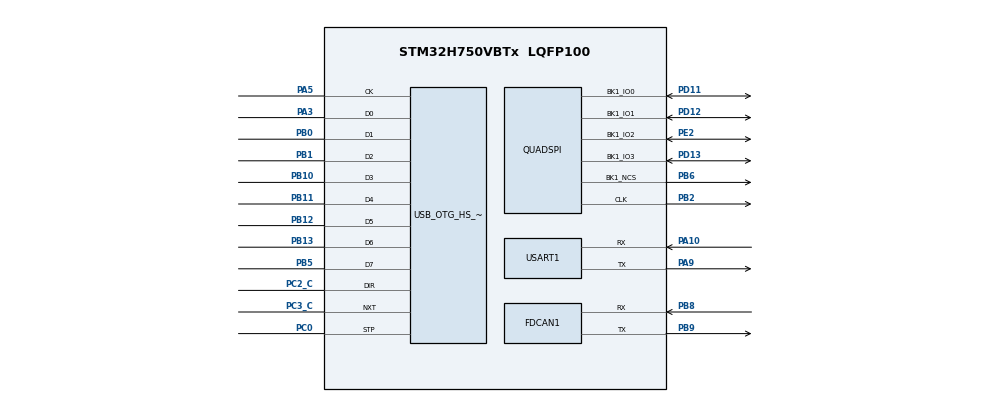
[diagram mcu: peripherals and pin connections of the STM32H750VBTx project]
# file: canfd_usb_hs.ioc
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CORTEX_M7.AccessPermission-Cortex_Memory_Protection_Unit_Region0_Settings=MPU_REGION_FULL_ACCESS
CORTEX_M7.AccessPermission-Cortex_Memory_Protection_Unit_Region1_Settings=MPU_REGION_PRIV_RO_URO
CORTEX_M7.AccessPermission_Spec=MPU_REGION_FULL_ACCESS
CORTEX_M7.BaseAddress-Cortex_Memory_Protection_Unit_Region1_Settings=0x8000000
CORTEX_M7.BaseAddress_Spec=0x24000000
CORTEX_M7.CPU_DCache=Enabled
CORTEX_M7.CPU_ICache=Enabled
CORTEX_M7.DisableExec_Spec=MPU_INSTRUCTION_ACCESS_ENABLE
CORTEX_M7.Enable-Cortex_Memory_Protection_Unit_Region0_Settings=MPU_REGION_ENABLE
CORTEX_M7.Enable-Cortex_Memory_Protection_Unit_Region1_Settings=MPU_REGION_ENABLE
CORTEX_M7.IsBufferable-Cortex_Memory_Protection_Unit_Region1_Settings=MPU_ACCESS_BUFFERABLE
CORTEX_M7.IsBufferable_Spec=MPU_ACCESS_BUFFERABLE
CORTEX_M7.IsCacheable-Cortex_Memory_Protection_Unit_Region1_Settings=MPU_ACCESS_CACHEABLE
CORTEX_M7.IsCacheable_Spec=MPU_ACCESS_CACHEABLE
CORTEX_M7.IsShareable_Spec=MPU_ACCESS_NOT_SHAREABLE
CORTEX_M7.MPU_Control=MPU_PRIVILEGED_DEFAULT
CORTEX_M7.Size-Cortex_Memory_Protection_Unit_Region0_Settings=MPU_REGION_SIZE_64KB
CORTEX_M7.Size-Cortex_Memory_Protection_Unit_Region1_Settings=MPU_REGION_SIZE_128KB
CORTEX_M7.Size_Spec=MPU_REGION_SIZE_512KB
CORTEX_M7.SubRegionDisable_Spec=0x0
CORTEX_M7.TypeExtField-Cortex_Memory_Protection_Unit_Region0_Settings=MPU_TEX_LEVEL1
CORTEX_M7.TypeExtField_Spec=MPU_TEX_LEVEL1
CORTEX_M7.default_mode_Activation=1
Dma.Request0=USART1_RX
Dma.Request1=USART1_TX
Dma.USART1_RX.0.Direction=DMA_PERIPH_TO_MEMORY
Dma.USART1_RX.0.EventEnable=DISABLE
Dma.USART1_RX.0.FIFOMode=DMA_FIFOMODE_DISABLE
Dma.USART1_RX.0.Instance=DMA1_Stream0
Dma.USART1_RX.0.MemDataAlignment=DMA_MDATAALIGN_BYTE
Dma.USART1_RX.0.MemInc=DMA_MINC_ENABLE
Dma.USART1_RX.0.Mode=DMA_CIRCULAR
Dma.USART1_RX.0.PeriphDataAlignment=DMA_PDATAALIGN_BYTE
Dma.USART1_RX.0.PeriphInc=DMA_PINC_DISABLE
Dma.USART1_RX.0.Polarity=HAL_DMAMUX_REQ_GEN_RISING
Dma.USART1_RX.0.Priority=DMA_PRIORITY_LOW
Dma.USART1_RX.0.RequestNumber=1
Dma.USART1_RX.0.SignalID=NONE
Dma.USART1_RX.0.SyncEnable=DISABLE
Dma.USART1_RX.0.SyncPolarity=HAL_DMAMUX_SYNC_NO_EVENT
Dma.USART1_RX.0.SyncRequestNumber=1
Dma.USART1_RX.0.SyncSignalID=NONE
Dma.USART1_TX.1.Direction=DMA_MEMORY_TO_PERIPH
Dma.USART1_TX.1.EventEnable=DISABLE
Dma.USART1_TX.1.FIFOMode=DMA_FIFOMODE_DISABLE
Dma.USART1_TX.1.Instance=DMA1_Stream1
Dma.USART1_TX.1.MemDataAlignment=DMA_MDATAALIGN_BYTE
Dma.USART1_TX.1.MemInc=DMA_MINC_ENABLE
Dma.USART1_TX.1.Mode=DMA_NORMAL
Dma.USART1_TX.1.PeriphDataAlignment=DMA_PDATAALIGN_BYTE
Dma.USART1_TX.1.PeriphInc=DMA_PINC_DISABLE
Dma.USART1_TX.1.Polarity=HAL_DMAMUX_REQ_GEN_RISING
Dma.USART1_TX.1.Priority=DMA_PRIORITY_LOW
Dma.USART1_TX.1.RequestNumber=1
Dma.USART1_TX.1.SignalID=NONE
Dma.USART1_TX.1.SyncEnable=DISABLE
Dma.USART1_TX.1.SyncPolarity=HAL_DMAMUX_SYNC_NO_EVENT
Dma.USART1_TX.1.SyncRequestNumber=1
Dma.USART1_TX.1.SyncSignalID=NONE
FDCAN1.AutoRetransmission=ENABLE
FDCAN1.CalculateBaudRateNominal=500000
FDCAN1.CalculateTimeBitNominal=2000
FDCAN1.CalculateTimeQuantumNominal=25.0
FDCAN1.DataPrescaler=2
FDCAN1.DataSyncJumpWidth=5
FDCAN1.DataTimeSeg1=14
FDCAN1.DataTimeSeg2=5
FDCAN1.ExtFiltersNbr=32
FDCAN1.FrameFormat=FDCAN_FRAME_FD_BRS
FDCAN1.NominalPrescaler=2
FDCAN1.NominalSyncJumpWidth=16
FDCAN1.NominalTimeSeg1=63
FDCAN1.NominalTimeSeg2=16
FDCAN1.RxBufferSize=FDCAN_DATA_BYTES_64
FDCAN1.RxFifo0ElmtSize=FDCAN_DATA_BYTES_64
FDCAN1.RxFifo0ElmtsNbr=32
FDCAN1.RxFifo1ElmtSize=FDCAN_DATA_BYTES_64
FDCAN1.StdFiltersNbr=64
FDCAN1.TransmitPause=ENABLE
FDCAN1.TxElmtSize=FDCAN_DATA_BYTES_64
FDCAN1.TxFifoQueueElmtsNbr=16
FREERTOS.Tasks01=defaultTask,0,128,StartDefaultTask,Default,NULL,Dynamic,NULL,NULL
FREERTOS.configCHECK_FOR_STACK_OVERFLOW=2
FREERTOS.configRECORD_STACK_HIGH_ADDRESS=1
FREERTOS.configUSE_COUNTING_SEMAPHORES=1
FREERTOS.configUSE_IDLE_HOOK=1
FREERTOS.configUSE_MALLOC_FAILED_HOOK=1
FREERTOS.configUSE_RECURSIVE_MUTEXES=1
HASH.SecureHashAlgorithmType=SHA256
HASH.pKey=__NULL
Mcu.Family=STM32H7
Mcu.Name=STM32H750VBTx
Mcu.Package=LQFP100
NVIC.DMA1_Stream0_IRQn=true\:5\:0\:false\:false\:true\:true\:false\:true\:true
NVIC.DMA1_Stream1_IRQn=true\:5\:0\:false\:false\:true\:true\:false\:true\:true
NVIC.FDCAN1_IT0_IRQn=true\:5\:0\:false\:false\:true\:true\:true\:true\:true
NVIC.OTG_HS_IRQn=true\:5\:0\:false\:false\:true\:true\:true\:true\:true
NVIC.PriorityGroup=NVIC_PRIORITYGROUP_4
NVIC.TIM1_UP_IRQn=true\:15\:0\:false\:false\:true\:false\:false\:true\:true
NVIC.TimeBase=TIM1_UP_IRQn
NVIC.TimeBaseIP=TIM1
NVIC.USART1_IRQn=true\:5\:0\:false\:false\:true\:true\:true\:true\:true
PA10.GPIO_PuPd=GPIO_PULLUP
PA10.GPIO_Speed=GPIO_SPEED_FREQ_LOW
PA10.Mode=Asynchronous
PA10.PinAttribute=Free
PA10.Signal=USART1_RX
PA13\ (JTMS/SWDIO).Mode=Serial_Wire
PA13\ (JTMS/SWDIO).PinAttribute=Free
PA13\ (JTMS/SWDIO).Signal=DEBUG_JTMS-SWDIO
PA14\ (JTCK/SWCLK).Mode=Serial_Wire
PA14\ (JTCK/SWCLK).PinAttribute=Free
PA14\ (JTCK/SWCLK).Signal=DEBUG_JTCK-SWCLK
PA3.Mode=Device_HS
PA3.PinAttribute=Free
PA3.Signal=USB_OTG_HS_ULPI_D0
PA5.Mode=Device_HS
PA5.PinAttribute=Free
PA5.Signal=USB_OTG_HS_ULPI_CK
PA9.GPIO_PuPd=GPIO_PULLUP
PA9.GPIO_Speed=GPIO_SPEED_FREQ_LOW
PA9.Mode=Asynchronous
PA9.PinAttribute=Free
PA9.Signal=USART1_TX
PB0.Mode=Device_HS
PB0.Signal=USB_OTG_HS_ULPI_D1
PB1.Mode=Device_HS
PB1.Signal=USB_OTG_HS_ULPI_D2
PB10.Mode=Device_HS
PB10.Signal=USB_OTG_HS_ULPI_D3
PB11.Mode=Device_HS
PB11.Signal=USB_OTG_HS_ULPI_D4
PB12.Mode=Device_HS
PB12.Signal=USB_OTG_HS_ULPI_D5
PB13.Mode=Device_HS
PB13.Signal=USB_OTG_HS_ULPI_D6
PB2.GPIO_PuPd=GPIO_PULLDOWN
PB2.GPIO_Speed=GPIO_SPEED_FREQ_MEDIUM
PB2.Mode=Single Bank 1
PB2.Signal=QUADSPI_CLK
PB5.Mode=Device_HS
PB5.Signal=USB_OTG_HS_ULPI_D7
PB6.GPIO_FM6=SYSCFG_PMCR_I2C_PB6_FMP
PB6.GPIO_PuPd=GPIO_PULLUP
PB6.GPIO_Speed=GPIO_SPEED_FREQ_MEDIUM
PB6.Mode=Single Bank 1
PB6.Signal=QUADSPI_BK1_NCS
PB8.GPIO_Speed=GPIO_SPEED_FREQ_MEDIUM
PB8.Mode=FDCAN_Activate
PB8.Signal=FDCAN1_RX
PB9.GPIO_Speed=GPIO_SPEED_FREQ_MEDIUM
PB9.Mode=FDCAN_Activate
PB9.Signal=FDCAN1_TX
PC0.Mode=Device_HS
PC0.Signal=USB_OTG_HS_ULPI_STP
PC2_C.Mode=Device_HS
PC2_C.Signal=USB_OTG_HS_ULPI_DIR
PC3_C.Mode=Device_HS
PC3_C.PinAttribute=Free
PC3_C.Signal=USB_OTG_HS_ULPI_NXT
PD11.GPIO_Speed=GPIO_SPEED_FREQ_HIGH
PD11.Mode=Single Bank 1
PD11.Signal=QUADSPI_BK1_IO0
PD12.GPIO_Speed=GPIO_SPEED_FREQ_HIGH
PD12.Mode=Single Bank 1
PD12.Signal=QUADSPI_BK1_IO1
PD13.GPIO_Speed=GPIO_SPEED_FREQ_HIGH
PD13.Mode=Single Bank 1
PD13.Signal=QUADSPI_BK1_IO3
PE2.GPIO_Speed=GPIO_SPEED_FREQ_HIGH
PE2.Mode=Single Bank 1
PE2.Signal=QUADSPI_BK1_IO2
PH0-OSC_IN\ (PH0).Mode=HSE-External-Oscillator
PH0-OSC_IN\ (PH0).Signal=RCC_OSC_IN
PH1-OSC_OUT\ (PH1).Mode=HSE-External-Oscillator
PH1-OSC_OUT\ (PH1).Signal=RCC_OSC_OUT
ProjectManager.HeapSize=0x2000
ProjectManager.StackSize=0x4000
ProjectManager.TargetToolchain=MDK-ARM V5.32
QUADSPI.ChipSelectHighTime=QSPI_CS_HIGH_TIME_1_CYCLE
QUADSPI.ClockPrescaler=100
QUADSPI.FifoThreshold=1
QUADSPI.FlashSize=15
RCC.ADCFreq_Value=400000000
RCC.APB1Freq_Value=120000000
RCC.APB2Freq_Value=120000000
RCC.APB3Freq_Value=120000000
RCC.APB4Freq_Value=120000000
RCC.CKPERSourceSelection=RCC_CLKPSOURCE_HSE
RCC.CortexFreq_Value=480000000
RCC.D1PPRE=RCC_APB3_DIV2
RCC.D2PPRE1=RCC_APB1_DIV2
RCC.D2PPRE2=RCC_APB2_DIV2
RCC.D3PPRE=RCC_APB4_DIV2
RCC.DIVM1=5
RCC.DIVM2=2
RCC.DIVM3=5
RCC.DIVN1=192
RCC.DIVN2=64
RCC.DIVN3=192
RCC.DIVQ1=12
RCC.DIVQ2=25
RCC.DIVQ3=8
RCC.DIVR1=8
RCC.HCLKFreq_Value=240000000
RCC.HPRE=RCC_HCLK_DIV2
RCC.PLL1_VCI_Range-AdvancedSettings=RCC_PLL1VCIRANGE_0
RCC.PLL1_VCO_SEL-AdvancedSettings=RCC_PLL1VCOMEDIUM
RCC.PLL2FRACN=0
RCC.PLL2_VCI_Range-AdvancedSettings=RCC_PLL2VCIRANGE_0
RCC.PLL3FRACN=0
RCC.PLL3_VCI_Range-AdvancedSettings=RCC_PLL3VCIRANGE_0
RCC.PLLFRACN=0
RCC.PLLSourceVirtual=RCC_PLLSOURCE_HSE
RCC.PWR_Regulator_Voltage_Scale=PWR_REGULATOR_VOLTAGE_SCALE0
RCC.ProductRev=revV
RCC.QSPICLockSelection=RCC_QSPICLKSOURCE_PLL
RCC.RCC_TIM_PRescaler_Selection=RCC_TIMPRES_DESACTIVATED
RCC.SYSCLKFreq_VALUE=480000000
RCC.SYSCLKSource=RCC_SYSCLKSOURCE_PLLCLK
RCC.USART16CLockSelection=RCC_USART16CLKSOURCE_PLL2
RCC.USBCLockSelection=RCC_USBCLKSOURCE_HSI48
RCC.USBFreq_Value=48000000
USART1.VirtualMode-Asynchronous=VM_ASYNC
USB_DEVICE.CLASS_NAME_HS=CDC
USB_DEVICE.VirtualMode-CDC_HS=Cdc
USB_DEVICE.VirtualModeHS=Cdc_HS
USB_OTG_HS.VirtualMode-Device_HS=Device_HS
VP_CRC_VS_CRC.Mode=CRC_Activate
VP_FREERTOS_VS_CMSIS_V1.Mode=CMSIS_V1
VP_HASH_VS_HASH.Mode=HASH_Activate
VP_RNG_VS_RNG.Mode=RNG_Activate
VP_SYS_VS_tim1.Mode=TIM1
VP_USB_DEVICE_VS_USB_DEVICE_CDC_HS.Mode=CDC_HS
board=custom

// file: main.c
/* USER CODE BEGIN Header */
/**
  ******************************************************************************
  * @file           : main.c
  * @brief          : Main program body
  ******************************************************************************
  * @attention
  *
  * Copyright (c) 2023 STMicroelectronics.
  * All rights reserved.
  *
  * This software is licensed under terms that can be found in the LICENSE file
  * in the root directory of this software component.
  * If no LICENSE file comes with this software, it is provided AS-IS.
  *
  ******************************************************************************
  */
/* USER CODE END Header */
#include "main.h"
#include "cmsis_os.h"
#include "crc.h"
#include "dma.h"
#include "fdcan.h"
#include "hash.h"
#include "quadspi.h"
#include "rng.h"
#include "usart.h"
#include "usb_device.h"
#include "gpio.h"
#include "lwrb.h"

/* USER CODE BEGIN PTD */
extern DMA_HandleTypeDef hdma_usart1_rx;
extern DMA_HandleTypeDef hdma_usart1_tx;
/* USER CODE END PTD */

void SystemClock_Config(void);
static void MPU_Config(void);
void MX_FREERTOS_Init(void);
/* USER CODE BEGIN PFP */

/* USART1 init function */
__ALIGNED(32) uint8_t dma_rx_buf[DMA_BUFFER_LENGTH] ;//__attribute__((section(".RAM_D2")));
__ALIGNED(32) uint8_t dma_tx_buf[DMA_BUFFER_LENGTH] ;//__attribute__((section(".RAM_D2"))));

/**
 * \brief           Ring buffer data array for RX DMA
 */
uint8_t usart_rx_rb_data[DMA_BUFFER_LENGTH];
volatile size_t usart_rx_dma_current_len = 0;
/**
 * \brief           Ring buffer data array for TX DMA
 */
uint8_t usart_tx_rb_data[DMA_BUFFER_LENGTH];

/* USER CODE BEGIN 0 */
volatile size_t usart_tx_dma_current_len;
/* USER CODE END 0 */

void EnableUSART_IDLE(void);

int main(void)
{

  /* MPU Configuration--------------------------------------------------------*/
  //MPU_Config();

  /* Enable I-Cache---------------------------------------------------------*/
  //SCB_EnableICache();

  /* Enable D-Cache---------------------------------------------------------*/
  //SCB_EnableDCache();

  /* MCU Configuration--------------------------------------------------------*/

  /* Reset of all peripherals, Initializes the Flash interface and the Systick. */
  HAL_Init();

  /* Configure the system clock */
  SystemClock_Config();

  /* Initialize all configured peripherals */
  MX_GPIO_Init();

  MX_CRC_Init();
  MX_FDCAN1_Init();
  MX_HASH_Init();
  MX_RNG_Init();
  //MX_QUADSPI_Init();

	MX_USB_DEVICE_Init();

  MX_DMA_Init();
  MX_USART1_UART_Init();
  /* USER CODE BEGIN 2 */
  EnableUSART_IDLE();
  /* USER CODE END 2 */

  /* Call init function for freertos objects (in freertos.c) */
  //MX_FREERTOS_Init();
  /* Start scheduler */
  //osKernelStart();

	while(1) {
		usart_tx_thread(0);

	}
}

/**
 * \brief           Process received data over UART
 * \note            Either process them directly or copy to other bigger buffer
 * \param[in]       data: Data to process
 * \param[in]       len: Length in units of bytes
 */
void usart_process_data(const void* data, size_t len) {
	memcpy(usart_rx_rb_data, data, len);
	usart_rx_dma_current_len += len;
}

/**
 * \brief           Check for new data received with DMA
 *
 * User must select context to call this function from:
 * - Only interrupts (DMA HT, DMA TC, UART IDLE) with same preemption priority level
 * - Only thread context (outside interrupts)
 *
 * If called from both context-es, exclusive access protection must be implemented
 * This mode is not advised as it usually means architecture design problems
 *
 * When IDLE interrupt is not present, application must rely only on thread context,
 * by manually calling function as quickly as possible, to make sure
 * data are read from raw buffer and processed.
 *
 * Not doing reads fast enough may cause DMA to overflow unread received bytes,
 * hence application will lost useful data.
 *
 * Solutions to this are:
 * - Improve architecture design to achieve faster reads
 * - Increase raw buffer size and allow DMA to write more data before this function is called
 */
void usart_rx_check()
{
    static size_t old_pos;

    /* Calculate current position in buffer and check for new data available */
    uint32_t pos = DMA_BUFFER_LENGTH - __HAL_DMA_GET_COUNTER(huart1.hdmarx);

    if (pos != old_pos) {                       /* Check change in received data */
        if (pos > old_pos) {                    /* Current position is over previous one */
            /*
             * Processing is done in "linear" mode.
             *
             * Application processing is fast with single data block,
             * length is simply calculated by subtracting pointers
             *
             * [   0   ]
             * [   1   ] <- old_pos |------------------------------------|
             * [   2   ]            |                                    |
             * [   3   ]            | Single block (len = pos - old_pos) |
             * [   4   ]            |                                    |
             * [   5   ]            |------------------------------------|
             * [   6   ] <- pos
             * [   7   ]
             * [ N - 1 ]
             */
            usart_process_data(&dma_rx_buf[old_pos], pos - old_pos);
        } else {
            /*
             * Processing is done in "overflow" mode..
             *
             * Application must process data twice,
             * since there are 2 linear memory blocks to handle
             *
             * [   0   ]            |---------------------------------|
             * [   1   ]            | Second block (len = pos)        |
             * [   2   ]            |---------------------------------|
             * [   3   ] <- pos
             * [   4   ] <- old_pos |---------------------------------|
             * [   5   ]            |                                 |
             * [   6   ]            | First block (len = N - old_pos) |
             * [   7   ]            |                                 |
             * [ N - 1 ]            |---------------------------------|
             */
            usart_process_data(&dma_rx_buf[old_pos], DMA_BUFFER_LENGTH - old_pos);
            if (pos > 0) {
                usart_process_data(&dma_rx_buf[0], pos);
            }
        }
        old_pos = pos;                          /* Save current position as old for next transfers */
    }
		else
		{
			osDelay(1);
		}
}

void HAL_UARTEx_RxEventCallback(UART_HandleTypeDef* huart, uint16_t Size)
{

		//本次串口接受32个字节容量
		//HAL_UART_Receive_DMA(&huart1,rx_buffer,32);//打开DMA接收
		//然后我发送了0x0C个字节的数据长度
		//那么此时__HAL_DMA_GET_COUNTER函数返回值就是0x14个字节，表示还能接收多少字节达到容量上限
		//_len_dmarev = 预先定义的接收总字节(0x20) - __HAL_DMA_GET_COUNTER()（0x14） = 0x0C
		//HAL_UART_DMAStop(huart);//Circular模式这里调用这个函数就失去了Circular模式的效果了
		//pos = DMA_BUFFER_LENGTH - __HAL_DMA_GET_COUNTER(huart1.hdmarx);

		SCB_InvalidateDCache_by_Addr((uint32_t*)dma_rx_buf, DMA_BUFFER_LENGTH);

		usart_rx_check();

		HAL_UARTEx_ReceiveToIdle_DMA(huart, dma_rx_buf, DMA_BUFFER_LENGTH);

}

void
usart_rx_dma_thread(void const* argument)
{
    /* Notify user to start sending data */
    while (1) {
        /* Simply call processing function */
        usart_rx_check();
    }
}

/**
 * \brief           Check if DMA is active and if not try to send data
 *
 * This function can be called either by application to start data transfer
 * or from DMA TX interrupt after previous transfer just finished
 *
 * \return          `1` if transfer just started, `0` if on-going or no data to transmit
 */

void
usart_start_tx_dma_transfer(void) {

    /*
     * First check if transfer is currently in-active,
     * by examining the value of usart_tx_dma_current_len variable.
     *
     * This variable is set before DMA transfer is started and cleared in DMA TX complete interrupt.
     *
     * It is not necessary to disable the interrupts before checking the variable:
     *
     * When usart_tx_dma_current_len == 0
     *    - This function is called by either application or TX DMA interrupt
     *    - When called from interrupt, it was just reset before the call,
     *         indicating transfer just completed and ready for more
     *    - When called from an application, transfer was previously already in-active
     *         and immediate call from interrupt cannot happen at this moment
     *
     * When usart_tx_dma_current_len != 0
     *    - This function is called only by an application.
     *    - It will never be called from interrupt with usart_tx_dma_current_len != 0 condition
     *
     * Disabling interrupts before checking for next transfer is advised
     * only if multiple operating system threads can access to this function w/o
     * exclusive access protection (mutex) configured,
     * or if application calls this function from multiple interrupts.
     *
     * This example assumes worst use case scenario,
     * hence interrupts are disabled prior every check
     */

    uint32_t primask;
    uint8_t started = 0;

    primask = __get_PRIMASK();
    __disable_irq();

		if (usart_tx_dma_current_len == 0)
		{
			__HAL_DMA_DISABLE(&hdma_usart1_tx);

			  //LL_DMA_ClearFlag_TC1(DMA1);
        //LL_DMA_ClearFlag_HT1(DMA1);
        //LL_DMA_ClearFlag_TE1(DMA1);
        //LL_DMA_ClearFlag_DME1(DMA1);
        //LL_DMA_ClearFlag_FE1(DMA1);

        __HAL_DMA_CLEAR_FLAG(&hdma_usart1_tx, __HAL_DMA_GET_TC_FLAG_INDEX(&hdma_usart1_tx));
        __HAL_DMA_CLEAR_FLAG(&hdma_usart1_tx, __HAL_DMA_GET_HT_FLAG_INDEX(&hdma_usart1_tx));
        __HAL_DMA_CLEAR_FLAG(&hdma_usart1_tx, __HAL_DMA_GET_TE_FLAG_INDEX(&hdma_usart1_tx));
				//__HAL_DMA_CLEAR_FLAG(&hdma_usart1_tx, __HAL_DMA_GET_DME_FLAG_INDEX(&hdma_usart1_tx));
				//__HAL_DMA_CLEAR_FLAG(&hdma_usart1_tx, __HAL_DMA_GET_FE_FLAG_INDEX(&hdma_usart1_tx));
        //__HAL_DMA_CLEAR_FLAG(&hdma_usart1_tx, __HAL_DMA_GET_GI_FLAG_INDEX(&hdma_usart1_tx));

        HAL_UART_Transmit_DMA(&huart1, (uint8_t*)usart_tx_rb_data, usart_tx_dma_current_len);

			__HAL_DMA_ENABLE(&hdma_usart1_tx);

		}
		__set_PRIMASK(primask);
}

void HAL_UART_TxCpltCallback(UART_HandleTypeDef *huart)
{
    usart_tx_dma_current_len = 0;           /* Clear length variable */
    usart_start_tx_dma_transfer();          /* Start sending more data */
}

void usart_tx_thread(void const* argument)
{
    /* Notify user to start sending data */
    uint8_t state, cmd, len, size, idx, err;
    uint8_t pkg_data[64];
		idx = 0;
    err = 0;
    state = 0;
		len = 0;
    while (1)
    {
        uint8_t b;

        /* Process RX ringbuffer */

        /* Packet format: START_BYTE, CMD, LEN[, DATA[0], DATA[len - 1]], STOP BYTE */
        /* DATA bytes are included only if LEN > 0 */
        /* An example, send sequence of these bytes: 55 FF 02 11 22 AA */

        /* Read byte by byte */

        if (size > 0 && ((len == 0 && usart_rx_dma_current_len > 0)
					|| (len > 0 && size >= len + 1 && usart_rx_dma_current_len > 0)))
        {
            switch (state)
            {
            case 0:
            {           /* Wait for start byte */
                if (b == 0x55)
                {
                    idx = 0;
                    ++state;
                }
                else
                {
                    //包处理异常
                    err = 1;
                }
            }
            break;
            case 1:
            {           /* Check packet command */
                len = b;
                ++state;
            }
            break;
            case 2:
            {           /* Packet data length */
                cmd = b;
								if (len > 0)
								{
									--len;
								}
								else
								{
									err = 1;
								}
                ++state;
            }
            break;
            default:
            {         /* End of packet */
                if (b == 0xAA) {
                    /* Packet is valid */

                    state = 0;
                    idx = 0;
                }
                else
                {
                    if (len > 0)
                    {
                        --len;          /* Decrease for received character */
                        pkg_data[idx] = b;//len=[1,0]  data=[11,22],len=0
                        ++idx;//[1,2]
                        ++state;
                    }
                    else
                    {
                        //包处理异常
                        err = 1;
                    }
                }
                break;
            }
            }

            /* Do other tasks ... */
        }
				else
				{
						osDelay(1);
				}
			}
}

void EnableUSART_IDLE(void)
{
    HAL_UARTEx_ReceiveToIdle_DMA(&huart1, dma_rx_buf, DMA_BUFFER_LENGTH);
}

void SystemClock_Config(void)
{
  RCC_OscInitTypeDef RCC_OscInitStruct = {0};
  RCC_ClkInitTypeDef RCC_ClkInitStruct = {0};

  /** Supply configuration update enable
  */
  HAL_PWREx_ConfigSupply(PWR_LDO_SUPPLY);

  /** Configure the main internal regulator output voltage
  */
  __HAL_PWR_VOLTAGESCALING_CONFIG(PWR_REGULATOR_VOLTAGE_SCALE1);

  while(!__HAL_PWR_GET_FLAG(PWR_FLAG_VOSRDY)) {}

  __HAL_RCC_SYSCFG_CLK_ENABLE();
  __HAL_PWR_VOLTAGESCALING_CONFIG(PWR_REGULATOR_VOLTAGE_SCALE0);

  while(!__HAL_PWR_GET_FLAG(PWR_FLAG_VOSRDY)) {}

  /** Initializes the RCC Oscillators according to the specified parameters
  * in the RCC_OscInitTypeDef structure.
  */
  RCC_OscInitStruct.OscillatorType = RCC_OSCILLATORTYPE_HSI48|RCC_OSCILLATORTYPE_HSE;
  RCC_OscInitStruct.HSEState = RCC_HSE_ON;
  RCC_OscInitStruct.HSI48State = RCC_HSI48_ON;
  RCC_OscInitStruct.PLL.PLLState = RCC_PLL_ON;
  RCC_OscInitStruct.PLL.PLLSource = RCC_PLLSOURCE_HSE;
  RCC_OscInitStruct.PLL.PLLM = 5;
  RCC_OscInitStruct.PLL.PLLN = 192;
  RCC_OscInitStruct.PLL.PLLP = 2;
  RCC_OscInitStruct.PLL.PLLQ = 12;
  RCC_OscInitStruct.PLL.PLLR = 8;
  RCC_OscInitStruct.PLL.PLLRGE = RCC_PLL1VCIRANGE_2;
  RCC_OscInitStruct.PLL.PLLVCOSEL = RCC_PLL1VCOWIDE;
  RCC_OscInitStruct.PLL.PLLFRACN = 0;
  if (HAL_RCC_OscConfig(&RCC_OscInitStruct) != HAL_OK)
  {
    Error_Handler();
  }

  /** Initializes the CPU, AHB and APB buses clocks
  */
  RCC_ClkInitStruct.ClockType = RCC_CLOCKTYPE_HCLK|RCC_CLOCKTYPE_SYSCLK
                              |RCC_CLOCKTYPE_PCLK1|RCC_CLOCKTYPE_PCLK2
                              |RCC_CLOCKTYPE_D3PCLK1|RCC_CLOCKTYPE_D1PCLK1;
  RCC_ClkInitStruct.SYSCLKSource = RCC_SYSCLKSOURCE_PLLCLK;
  RCC_ClkInitStruct.SYSCLKDivider = RCC_SYSCLK_DIV1;
  RCC_ClkInitStruct.AHBCLKDivider = RCC_HCLK_DIV2;
  RCC_ClkInitStruct.APB3CLKDivider = RCC_APB3_DIV2;
  RCC_ClkInitStruct.APB1CLKDivider = RCC_APB1_DIV2;
  RCC_ClkInitStruct.APB2CLKDivider = RCC_APB2_DIV2;
  RCC_ClkInitStruct.APB4CLKDivider = RCC_APB4_DIV2;

  if (HAL_RCC_ClockConfig(&RCC_ClkInitStruct, FLASH_LATENCY_4) != HAL_OK)
  {
    Error_Handler();
  }
}

/* MPU Configuration */

void MPU_Config(void)
{
  MPU_Region_InitTypeDef MPU_InitStruct = {0};

  /* Disables the MPU */
  HAL_MPU_Disable();

  /** Initializes and configures the Region and the memory to be protected
  */
  MPU_InitStruct.Enable = MPU_REGION_ENABLE;
  MPU_InitStruct.Number = MPU_REGION_NUMBER0;
  MPU_InitStruct.BaseAddress = 0x24000000;
  MPU_InitStruct.Size = MPU_REGION_SIZE_512KB;
  MPU_InitStruct.SubRegionDisable = 0x0;
  MPU_InitStruct.TypeExtField = MPU_TEX_LEVEL1;
  MPU_InitStruct.AccessPermission = MPU_REGION_FULL_ACCESS;
  MPU_InitStruct.DisableExec = MPU_INSTRUCTION_ACCESS_ENABLE;
  MPU_InitStruct.IsShareable = MPU_ACCESS_NOT_SHAREABLE;
  MPU_InitStruct.IsCacheable = MPU_ACCESS_CACHEABLE;
  MPU_InitStruct.IsBufferable = MPU_ACCESS_BUFFERABLE;

  HAL_MPU_ConfigRegion(&MPU_InitStruct);
  /* Enables the MPU */
  HAL_MPU_Enable(MPU_PRIVILEGED_DEFAULT);

}

void HAL_TIM_PeriodElapsedCallback(TIM_HandleTypeDef *htim)
{
  if (htim->Instance == TIM1) {
    HAL_IncTick();
  }
}

void Error_Handler(void)
{
  __disable_irq();
  while (1)
  {
  }
}
